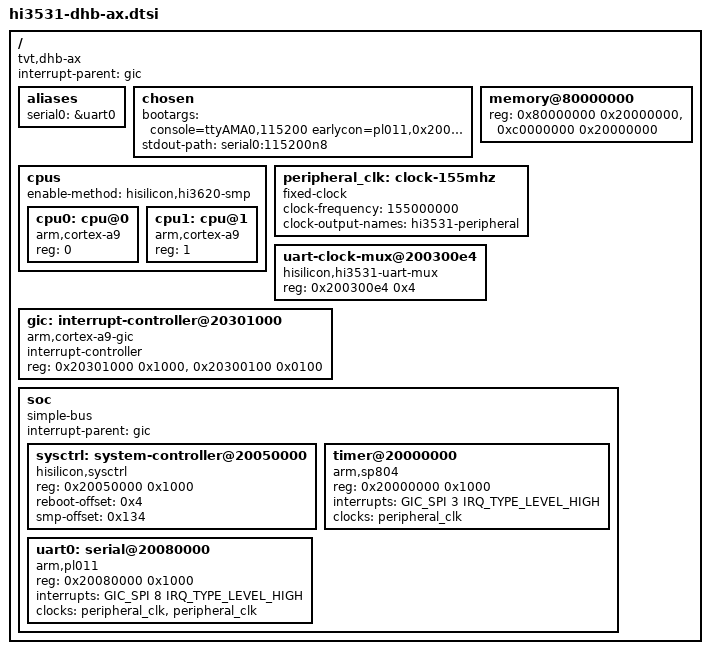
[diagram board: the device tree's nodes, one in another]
// SPDX-License-Identifier: GPL-2.0-only
/*
 * Shared base for the LTS LTD2704XE-P DVR, built on the Shenzhen TVT
 * motherboard marked DHB_AX V1.2 (HiSilicon Hi3531 "godnet").
 *
 * Only hardware confirmed against the running DVR's /proc/iomem,
 * /proc/interrupts and early boot log is described here.
 */

#include <dt-bindings/interrupt-controller/arm-gic.h>

/ {
	compatible = "tvt,dhb-ax", "hisilicon,hi3531";

	#address-cells = <1>;
	#size-cells = <1>;
	interrupt-parent = <&gic>;

	aliases {
		serial0 = &uart0;
	};

	chosen {
		bootargs = "console=ttyAMA0,115200 earlycon=pl011,0x20080000 keep_bootcon ignore_loglevel rdinit=/init";
		stdout-path = "serial0:115200n8";
	};

	/*
	 * Both cores.  The vendor releases CPU1 by writing the physical
	 * address of the secondary entry point to SYS_CTRL + 0x134 and then
	 * sending a soft interrupt, which the boot monitor is waiting for.
	 * That is exactly what mainline's "hisilicon,hi3620-smp" method does,
	 * so no new code is needed: it enables the Cortex-A9 SCU, finds the
	 * sysctrl node below, and uses its smp-offset.  The CPU power-control
	 * step in that method no-ops here because this board has no
	 * "hisilicon,hi3620-cpu-ctrl" node.
	 */
	cpus {
		#address-cells = <1>;
		#size-cells = <0>;
		enable-method = "hisilicon,hi3620-smp";

		cpu0: cpu@0 {
			compatible = "arm,cortex-a9";
			device_type = "cpu";
			reg = <0>;
		};

		cpu1: cpu@1 {
			compatible = "arm,cortex-a9";
			device_type = "cpu";
			reg = <1>;
		};
	};

	/*
	 * Two independent 512 MiB banks.  With U-Boot's data cache evicted,
	 * each bank retained distinct patterns 256 MiB apart and the words at
	 * 0x9f000000 and 0xdf000000 retained different patterns near the top
	 * of their respective banks.  A separate write confirmed that
	 * 0xa8000000 aliases 0x88000000, but that address is in the unmapped
	 * hole between the controllers; it does not imply that DDR1 at
	 * 0xc0000000 aliases DDR0.
	 *
	 * The vendor's "DRAM: 256 MiB" is a hardcoded constant in their U-Boot
	 * board file, not a measurement.
	 */
	memory@80000000 {
		device_type = "memory";
		reg = <0x80000000 0x20000000>,
		      <0xc0000000 0x20000000>;
	};

	/*
	 * No reserved-memory node, deliberately.
	 *
	 * Earlier revisions reserved 32 MiB at 0x8e000000, described as "the
	 * stock firmware's media carveout".  That description was wrong on two
	 * counts.  The vendor passes mem=224M, so their carveout is everything
	 * above 0x8e000000 -- 288 MiB on a 512 MiB board, not 32 MiB.  The
	 * 32 MiB figure was an artefact of believing the board had 256 MiB.
	 * And this port already claims 0x90000000-0x9fffffff, which is inside
	 * that same vendor region, and has passed sustained DMA tests there.
	 *
	 * U-Boot's video buffers sit at 0xc0000000 and 0xc1000000 in DDR1.
	 * They are not aliases of the kernel load area.  The display path only
	 * reads those buffers and this port does not use it, so it cannot
	 * corrupt RAM and does not justify withholding the bank from Linux.
	 *
	 * DDR0 has also been verified by filling nearly all of it with a known
	 * pattern and checksumming it.  If a future change makes an abandoned
	 * media engine write either bank, that test should be extended across
	 * DDR1 before the change is accepted.
	 */

	peripheral_clk: clock-155mhz {
		compatible = "fixed-clock";
		#clock-cells = <0>;
		clock-frequency = <155000000>;
		clock-output-names = "hi3531-peripheral";
	};

	uart-clock-mux@200300e4 {
		compatible = "hisilicon,hi3531-uart-mux";
		reg = <0x200300e4 0x4>;
	};

	gic: interrupt-controller@20301000 {
		compatible = "arm,cortex-a9-gic";
		#interrupt-cells = <3>;
		#address-cells = <0>;
		interrupt-controller;
		reg = <0x20301000 0x1000>,
		      <0x20300100 0x0100>;
	};

	soc: soc {
		compatible = "simple-bus";
		#address-cells = <1>;
		#size-cells = <1>;
		interrupt-parent = <&gic>;
		ranges;

		/*
		 * Restart method.  The vendor 3.0.8 arch_reset() writes to
		 * SYS_CTRL_BASE + REG_SC_SYSRES, which its platform.h defines
		 * as 0x20050000 + 0x4.  That is the same shape as the stock
		 * "hisilicon,sysctrl" reboot support, so no driver change is
		 * needed.
		 */
		sysctrl: system-controller@20050000 {
			compatible = "hisilicon,sysctrl";
			reg = <0x20050000 0x1000>;
			reboot-offset = <0x4>;
			/* Where CPU1's entry point is written; SMP_COREX_START_ADDR_REG
			 * in the vendor platsmp.h. */
			smp-offset = <0x134>;
		};

		timer@20000000 {
			compatible = "arm,sp804", "arm,primecell";
			reg = <0x20000000 0x1000>;
			interrupts = <GIC_SPI 3 IRQ_TYPE_LEVEL_HIGH>;
			clocks = <&peripheral_clk>;
			clock-names = "apb_pclk";
		};

		uart0: serial@20080000 {
			compatible = "arm,pl011", "arm,primecell";
			reg = <0x20080000 0x1000>;
			interrupts = <GIC_SPI 8 IRQ_TYPE_LEVEL_HIGH>;
			clocks = <&peripheral_clk>, <&peripheral_clk>;
			clock-names = "uartclk", "apb_pclk";
		};
	};
};
